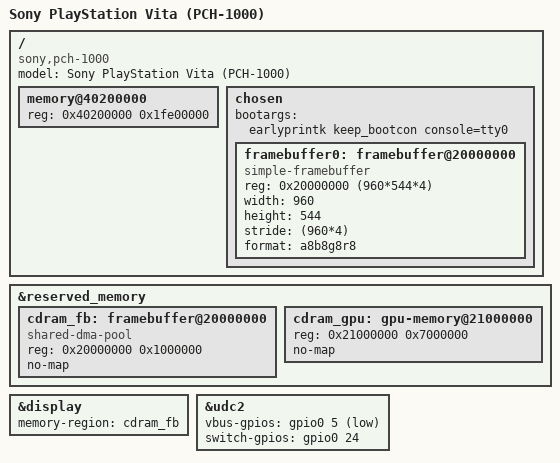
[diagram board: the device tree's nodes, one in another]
// SPDX-License-Identifier: GPL-2.0
/*
 * Device Tree Source for the PlayStation Vita 1000 (PCH-1000, OLED)
 */

/dts-v1/;

#include "vita.dtsi"

/ {
	model = "Sony PlayStation Vita (PCH-1000)";
	compatible = "sony,pch-1000", "sony,vita", "vita,vita";

	/*
	 * 512 MiB LPDDR2 at 0x40000000 [WIKI Physical_Memory].
	 * The first 2 MiB (0x40000000-0x401FFFFF) are the secure world's.
	 */
	memory@40200000 {
		device_type = "memory";
		reg = <0x40200000 0x1fe00000>;
	};

	chosen {
		bootargs = "earlyprintk keep_bootcon console=tty0";

		/* Set up by the boot loader in CDRAM (0x20000000, 128 MiB) */
		framebuffer0: framebuffer@20000000 {
			compatible = "simple-framebuffer";
			reg = <0x20000000 (960*544*4)>;
			width = <960>;
			height = <544>;
			stride = <(960*4)>;
			format = "a8b8g8r8";
			status = "okay";
		};
	};
};

&reserved_memory {
	/*
	 * Scanout: the boot loader's 960x544x4 framebuffer at its start
	 * (simple-framebuffer), or the display driver's buffers (eight
	 * 960x544x4 buffers, each taking 2 MiB of the pool).
	 */
	cdram_fb: framebuffer@20000000 {
		compatible = "shared-dma-pool";
		reg = <0x20000000 0x1000000>;
		no-map;
	};

	/* The rest of CDRAM: the GPU's buffer objects */
	cdram_gpu: gpu-memory@21000000 {
		reg = <0x21000000 0x7000000>;
		no-map;
	};
};

/*
 * The OLED head. Disabled here: the boot loader enables it and removes the
 * simple-framebuffer for vita.display=native, and enables it next to the
 * simple-framebuffer for vita.display=handover.
 */
&display {
	memory-region = <&cdram_fb>;
};

/*
 * udcd reads this model's VBUS from GPIO0 port 5 (low while a cable supplies
 * it) as well as Pervasive2, and drives GPIO0 port 24 while the controller
 * runs (hardware info 0x40xxxx, udcd.skprx 0x810082a0, 0x81006554). The
 * PCH-1000 switch is not verified on hardware.
 */
&udc2 {
	vbus-gpios = <&gpio0 5 GPIO_ACTIVE_LOW>;
	switch-gpios = <&gpio0 24 GPIO_ACTIVE_HIGH>;
};
